# DSS register map
Vendor: Texas Instruments
Peripheral module from a debugger description file (folder TDA3x).
Registers are 32-bit, access per field, reset 0x0 unless marked. A register's access mark holds for its fields unless they carry their own. Offsets are as the file gives them; lines under a group give offsets from that group; [hi:lo] are bit positions; {n}, {i} and the like mark numbered series; 'fields as' and 'values as' point back to an identical list; <NAME> marks a mode.

## DSS
0x00 DSS_REVISION ro reset not defined — This register contains the DSS revision number.
  [31:0] REVISION — IP revision
0x10 DSS_SYSCONFIG reset 0x2 — This register controls the various parameters of the OCP interface
  [1:0] SIDLEMODE rw
    0=FIDLE (Force-idle.An idle request is acknowledged unconditionally); 1=NIDLE (No-idle. An idle request is never acknowledged); 2=SIDLE (Smart-idle. Acknowledgement to an idle request is given based on the internal activity of the module.)
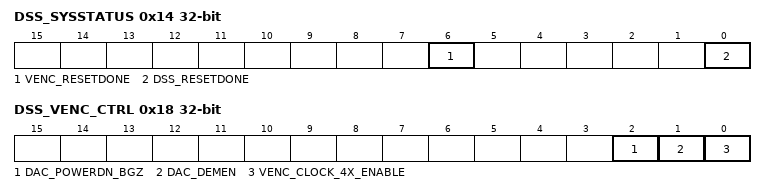
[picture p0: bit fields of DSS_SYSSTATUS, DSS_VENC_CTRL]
0x14 DSS_SYSSTATUS ro — This register provides status information about the module.
  [6] VENC_RESETDONE — Reset status of VENC module
    0=Internal_module_reset_is_on-going; 1=Reset_completed
  [0] DSS_RESETDONE — Reset status of DISPC/DSS
    0=RSTACT (Internal module reset is on-going); 1=RSTCOMP (Reset completed)
0x18 DSS_VENC_CTRL — This register contains control bits corresponding to the VENC instance in DSS
  [2] DAC_POWERDN_BGZ rw — DAC power down band gap control
    0=DISABLE (DAC power down band gap disabled); 1=ENABLE (DAC power down band gap enabled)
  [1] DAC_DEMEN rw — DAC Dynamic Element Matching Enable
    0=DISABLE (DAC Dynamic Element Matching disabled); 1=ENABLE (DAC Dynamic Element Matching enabled)
  [0] VENC_CLOCK_4X_ENABLE rw — VENC Clock CLK4X Enable. This bit is used to control the CLK4X clock gating.
    0=DISABLE; 1=ENABLE
0x1C DSS_DPI_CTRL reset 0x1 — This register contains control bits corresponding to the DPI interface in DSS
  [0] DPI_ENABLE rw — Enable DPI interface. This bit is used to enable the DPI interface.
    0=DISABLE (Disable - PCLK is gated); 1=ENABLE
0x40 DSS_DEBUG_CFG — Debug configuration
  [2:0] CFG rw — Defines which debug bus to provide on the DSS debug bus connected at the top. Only values 0, 1, 2, 3, 4, and 5 can be used.The following values are not supported on device level, as the features listed are not supported in this family of devices. enum=DSI1_A .
    0=DISPC (select DISPC Debug bus); 1=DSI1_A (select DSI1_A Debug bus); 2=DSI1_B (select DSI1_B Debug bus); 3=DP_A (select DP_A Debug bus); 4=DP_B (select DP_B Debug bus); 5=HDMI (select HDMI Debug bus)
